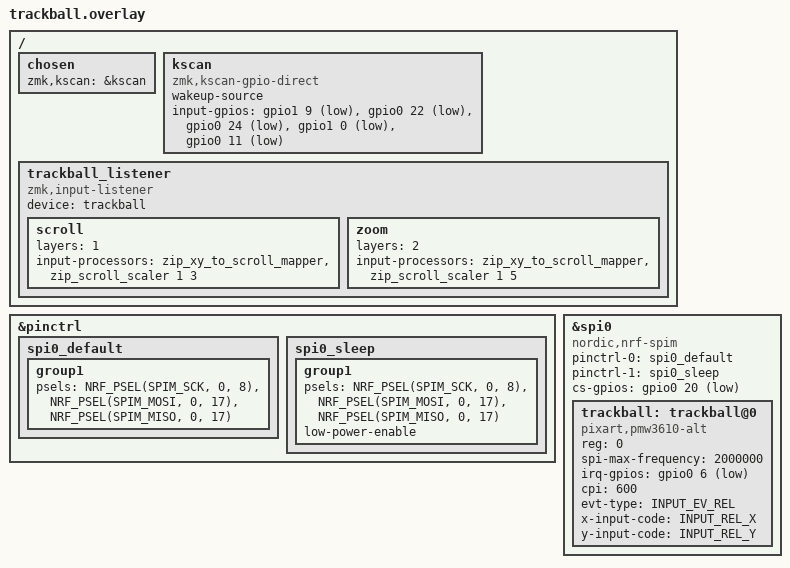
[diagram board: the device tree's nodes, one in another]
#include <zephyr/dt-bindings/input/input-event-codes.h>
#include <dt-bindings/zmk/input_transform.h>
#include <input/processors/code_mapper.dtsi>
#include <input/processors/scaler.dtsi>

/ {
    chosen {
        zmk,kscan = &kscan;
    };

    kscan: kscan {
        compatible = "zmk,kscan-gpio-direct";
        wakeup-source;
        input-gpios
            = <&gpio1 9  (GPIO_ACTIVE_LOW | GPIO_PULL_UP)>
            , <&gpio0 22 (GPIO_ACTIVE_LOW | GPIO_PULL_UP)>
            , <&gpio0 24 (GPIO_ACTIVE_LOW | GPIO_PULL_UP)>
            , <&gpio1 0  (GPIO_ACTIVE_LOW | GPIO_PULL_UP)>
            , <&gpio0 11 (GPIO_ACTIVE_LOW | GPIO_PULL_UP)>
            ;
    };

    trackball_listener: trackball_listener {
        compatible = "zmk,input-listener";
        device = <&trackball>;

        /* scroll layer: remap XY to scroll wheel */
        scroll {
            layers = <1>;
            input-processors = <&zip_xy_to_scroll_mapper>, <&zip_scroll_scaler 1 3>;
        };

        /* zoom layer: scroll + even slower for precision */
        zoom {
            layers = <2>;
            input-processors = <&zip_xy_to_scroll_mapper>, <&zip_scroll_scaler 1 5>;
        };
    };
};

&pinctrl {
    spi0_default: spi0_default {
        group1 {
            psels = <NRF_PSEL(SPIM_SCK, 0, 8)>,
                    <NRF_PSEL(SPIM_MOSI, 0, 17)>,
                    <NRF_PSEL(SPIM_MISO, 0, 17)>;
        };
    };
    spi0_sleep: spi0_sleep {
        group1 {
            psels = <NRF_PSEL(SPIM_SCK, 0, 8)>,
                    <NRF_PSEL(SPIM_MOSI, 0, 17)>,
                    <NRF_PSEL(SPIM_MISO, 0, 17)>;
            low-power-enable;
        };
    };
};

&spi0 {
    status = "okay";
    compatible = "nordic,nrf-spim";
    pinctrl-0 = <&spi0_default>;
    pinctrl-1 = <&spi0_sleep>;
    pinctrl-names = "default", "sleep";
    cs-gpios = <&gpio0 20 GPIO_ACTIVE_LOW>;

    trackball: trackball@0 {
        compatible = "pixart,pmw3610-alt";
        reg = <0>;
        spi-max-frequency = <2000000>;
        irq-gpios = <&gpio0 6 (GPIO_ACTIVE_LOW | GPIO_PULL_UP)>;
        cpi = <600>;
        evt-type = <INPUT_EV_REL>;
        x-input-code = <INPUT_REL_X>;
        y-input-code = <INPUT_REL_Y>;
    };
};
